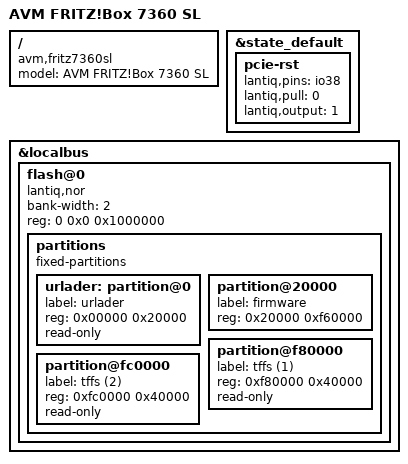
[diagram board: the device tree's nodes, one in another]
// SPDX-License-Identifier: GPL-2.0-or-later OR MIT

#include "vr9_avm_fritz736x.dtsi"

/ {
	compatible = "avm,fritz7360sl", "avm,fritz736x", "lantiq,xway", "lantiq,vr9";
	model = "AVM FRITZ!Box 7360 SL";
};

&state_default {
	pcie-rst {
		lantiq,pins = "io38";
		lantiq,pull = <0>;
		lantiq,output = <1>;
	};
};

&localbus {
	flash@0 {
		compatible = "lantiq,nor";
		bank-width = <2>;
		reg = <0 0x0 0x1000000>;

		partitions {
			#address-cells = <1>;
			#size-cells = <1>;
			compatible = "fixed-partitions";

			urlader: partition@0 {
				label = "urlader";
				reg = <0x00000 0x20000>;
				read-only;
			};

			partition@20000 {
				label = "firmware";
				reg = <0x20000 0xf60000>;
			};

			partition@f80000 {
				label = "tffs (1)";
				reg = <0xf80000 0x40000>;
				read-only;
			};

			partition@fc0000 {
				label = "tffs (2)";
				reg = <0xfc0000 0x40000>;
				read-only;
			};
		};
	};
};
